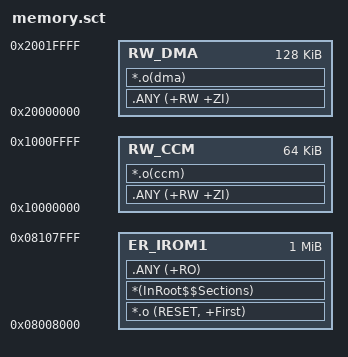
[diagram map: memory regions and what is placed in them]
; *************************************************************
; *** Scatter-Loading Description File generated by uVision ***
; *************************************************************

LR_IROM1 0x08008000 0x00100000  {    ; load region size_region
  ER_IROM1 0x08008000 0x00100000  {  ; load address = execution address
   *.o (RESET, +First)
   *(InRoot$$Sections)
   .ANY (+RO)
  }
  RW_CCM 0x10000000 0x00010000  {  ; RW data
   .ANY (+RW +ZI)
   *.o(ccm)
  }
  RW_DMA 0x20000000 0x00020000  {  ; RW data
   .ANY (+RW +ZI)
   *.o(dma)
  }
}

